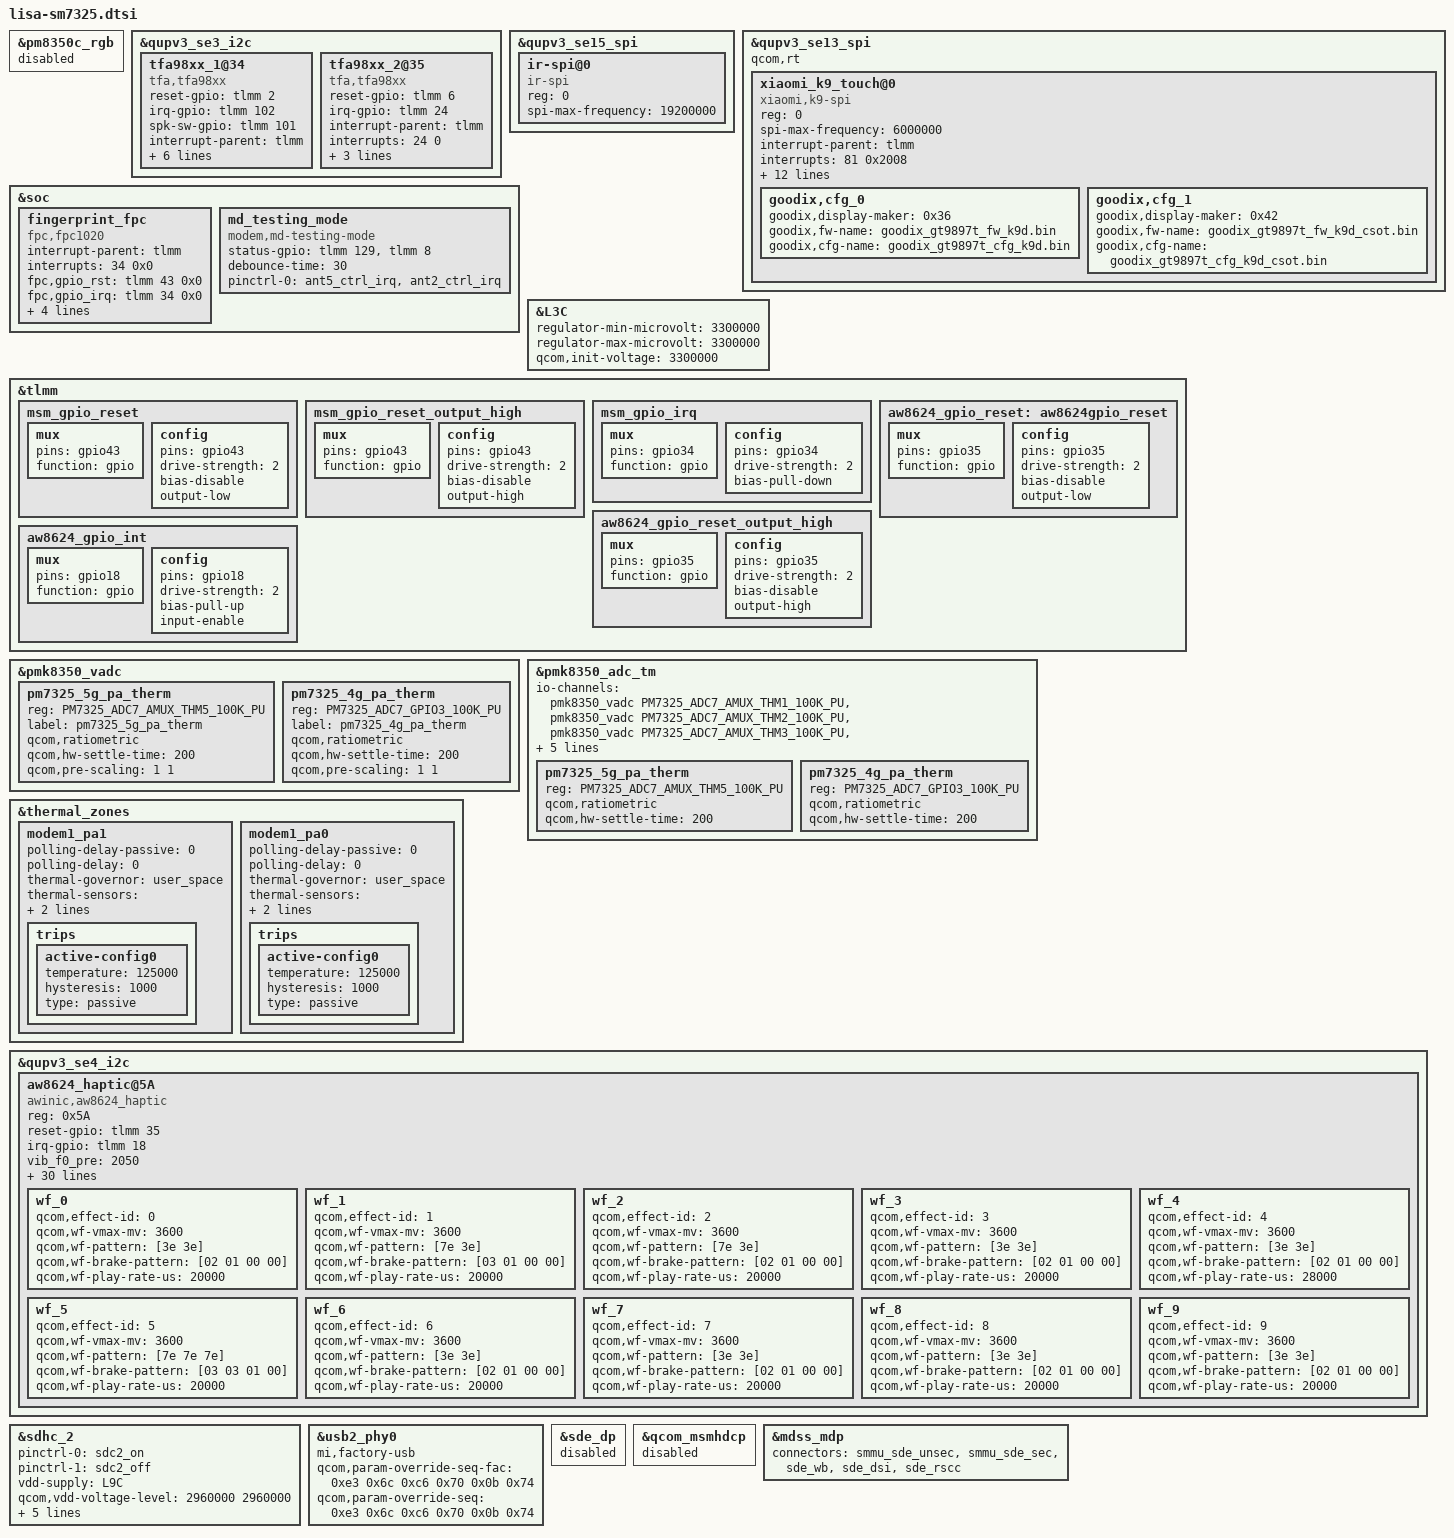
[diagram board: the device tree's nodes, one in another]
/*
this file is for attribution only of lisa
And public attribution of xiaomi platforms
*/

#include "lisa-pinctrl.dtsi"
#include "xiaomi-sm7325-common.dtsi"
#include "camera/lisa-sm7325-camera-sensor.dtsi"
#include "lisa-audio-overlay.dtsi"

&pm8350c_rgb {
	status = "disabled";
};

&qupv3_se3_i2c {
	status = "ok";
	tfa98xx_1@34 {
		compatible = "tfa,tfa98xx";
		reset-gpio = <&tlmm 2 0>;
		irq-gpio = <&tlmm 102 0>;
		spk-sw-gpio = <&tlmm 101 0>;
		interrupt-parent = <&tlmm>;
		interrupts = <102 0>;
		interrupt-names = "smartpa_irq";
		pinctrl-names = "default", "sleep";
		pinctrl-0 = <&smartpa_top_int_active &smartpa_enable_active &spk_sw_active>;
		pinctrl-1 = <&smartpa_top_int_suspend &smartpa_enable_suspend &spk_sw_inactive>;
		reg = <0x34>;
		status = "ok";
	};
	tfa98xx_2@35 {
		compatible = "tfa,tfa98xx";
		reset-gpio = <&tlmm 6 0>;
		irq-gpio = <&tlmm 24 0>;
		interrupt-parent = <&tlmm>;
		interrupts = <24 0>;
		interrupt-names = "smartpa_irq";
		pinctrl-names = "default", "sleep";
		pinctrl-0 = <&smartpa_bot_int_active>;
		pinctrl-1 = <&smartpa_bot_int_suspend>;
		reg = <0x35>;
		status = "ok";
	};
};

&qupv3_se15_spi {
	status = "ok";
	ir-spi@0 {
		compatible = "ir-spi";
		reg = <0>;
		spi-max-frequency = <19200000>;
		status = "ok";
	};
};

&qupv3_se13_spi {
	status = "ok";
	qcom,rt;
	xiaomi_k9_touch@0{
		compatible = "xiaomi,k9-spi";
		reg = <0>;
		spi-max-frequency = <6000000>;
		interrupt-parent = <&tlmm>;
		interrupts = <81 0x2008>;

		goodix,avdd-name = "avdd";
		goodix,iovdd-name = "iovdd";
		avdd-supply = <&L7C>;
		iovdd-supply = <&L2C>;

		goodix,reset-gpio = <&tlmm 105 0x00>;
		goodix,irq-gpio = <&tlmm 81 0x2800>;
		goodix,irq-flags = <2>;
		goodix,panel-max-x = <1080>;
		goodix,panel-max-y = <2400>;
		goodix,panel-max-w = <255>;
		goodix,panel-max-p = <4096>;

		goodix,config-array-size = <2>;
		goodix,cfg_0 {
			goodix,display-maker = <0x36>;
			goodix,fw-name = "goodix_gt9897t_fw_k9d.bin";
			goodix,cfg-name = "goodix_gt9897t_cfg_k9d.bin";
		};
		goodix,cfg_1 {
			goodix,display-maker = <0x42>;
			goodix,fw-name = "goodix_gt9897t_fw_k9d_csot.bin";
			goodix,cfg-name = "goodix_gt9897t_cfg_k9d_csot.bin";
		};

		/*pinctrl-names = "pmx_ts_active", "pmx_ts_suspend", "pmx_ts_release";*/
		/*pinctrl-0 = <&mi_ts_active>;*/
		/*pinctrl-1 = <&ts_int_suspend &ts_reset_suspend>;*/
		/*pinctrl-2 = <&ts_release>;*/
		/*vdd-supply = <&touch_avdd_vreg>;*/
		/*vcc_i2c-supply = <&L2C>;*/
	};
};

&soc {
	fingerprint_fpc {
		status = "ok";
		compatible = "fpc,fpc1020";
		interrupt-parent = <&tlmm>;
		interrupts = <34 0x0>;
		fpc,gpio_rst    = <&tlmm 43 0x0>;
		fpc,gpio_irq    = <&tlmm 34 0x0>;
		fp_vdd_vreg-supply = <&L3C>;
		pinctrl-names = "fpc1020_reset_reset",
						"fpc1020_reset_active",
						"fpc1020_irq_active";

		pinctrl-0 = <&msm_gpio_reset>;
		pinctrl-1 = <&msm_gpio_reset_output_high>;
		pinctrl-2 = <&msm_gpio_irq>;
	};

	md_testing_mode {
		compatible = "modem,md-testing-mode";
		status-gpio = <&tlmm 129 0x00>,
                <&tlmm 8 0x00>;
		debounce-time = <30>;
		pinctrl-names = "default";
		pinctrl-0 = <&ant5_ctrl_irq &ant2_ctrl_irq>;
	};
};

&L3C {
	regulator-min-microvolt = <3300000>;
	regulator-max-microvolt = <3300000>;
	qcom,init-voltage = <3300000>;
};

&tlmm {
                /* FP_RESET_N */
        msm_gpio_reset: msm_gpio_reset {
                mux {
                        pins = "gpio43";
                        function = "gpio";
                };
                config {
                        pins = "gpio43";
                        drive-strength = <2>;
                        bias-disable;
                        output-low;
                };
        };
                /* FP_RESET_N, state device active*/
        msm_gpio_reset_output_high: msm_gpio_reset_output_high {
                mux {
                        pins = "gpio43";
                        function = "gpio";
                };
                config {
                        pins = "gpio43";
                        drive-strength = <2>;
                        bias-disable;
                        output-high;
                };
        };
                /* FP_INT_N */
        msm_gpio_irq: msm_gpio_irq {
                mux {
                        pins = "gpio34";
                        function = "gpio";
                };
                config {
                        pins = "gpio34";
                        drive-strength = <2>;
                        bias-pull-down;
                };
        };
};

&pmk8350_vadc {
	pm7325_5g_pa_therm {
		reg = <PM7325_ADC7_AMUX_THM5_100K_PU>;
		label = "pm7325_5g_pa_therm";
		qcom,ratiometric;
		qcom,hw-settle-time = <200>;
		qcom,pre-scaling = <1 1>;
        };
	pm7325_4g_pa_therm {
		reg = <PM7325_ADC7_GPIO3_100K_PU>;
                label = "pm7325_4g_pa_therm";
		qcom,ratiometric;
		qcom,hw-settle-time = <200>;
		qcom,pre-scaling = <1 1>;
	};
};

&pmk8350_adc_tm {
	io-channels = <&pmk8350_vadc PM7325_ADC7_AMUX_THM1_100K_PU>,
			<&pmk8350_vadc PM7325_ADC7_AMUX_THM2_100K_PU>,
			<&pmk8350_vadc PM7325_ADC7_AMUX_THM3_100K_PU>,
			<&pmk8350_vadc PM7325_ADC7_AMUX_THM4_100K_PU>,
			<&pmk8350_vadc PMK8350_ADC7_AMUX_THM1_100K_PU>,
                        <&pmk8350_vadc PM7325B_ADC7_GPIO2_100K_PU>,
                        <&pmk8350_vadc PM7325_ADC7_AMUX_THM5_100K_PU>,
                        <&pmk8350_vadc PM7325_ADC7_GPIO3_100K_PU>;
	pm7325_5g_pa_therm {
		reg = <PM7325_ADC7_AMUX_THM5_100K_PU>;
		qcom,ratiometric;
		qcom,hw-settle-time = <200>;
	};
	pm7325_4g_pa_therm {
		reg = <PM7325_ADC7_GPIO3_100K_PU>;
		qcom,ratiometric;
		qcom,hw-settle-time = <200>;
	};
};

&thermal_zones {
	modem1_pa1 {
		polling-delay-passive = <0>;
		polling-delay = <0>;
		thermal-governor = "user_space";
		thermal-sensors = <&pmk8350_adc_tm PM7325_ADC7_AMUX_THM5_100K_PU>;
		wake-capable-sensor;
		trips {
			active-config0 {
				temperature = <125000>;
				hysteresis = <1000>;
				type = "passive";
			};
		};
	};

	modem1_pa0 {
		polling-delay-passive = <0>;
		polling-delay = <0>;
		thermal-governor = "user_space";
		thermal-sensors = <&pmk8350_adc_tm PM7325_ADC7_GPIO3_100K_PU>;
		wake-capable-sensor;
		trips {
			active-config0 {
				temperature = <125000>;
				hysteresis = <1000>;
				type = "passive";
			};
		};
	};
};
&qupv3_se4_i2c {
     status = "ok";
     aw8624_haptic@5A {
		compatible = "awinic,aw8624_haptic";
		reg = <0x5A>;
		reset-gpio = <&tlmm 35 0>;
		irq-gpio = <&tlmm 18 0>;
		vib_f0_pre = < 2050 >;
		vib_f0_cali_percen = < 7 >;
		vib_cont_drv_lev = < 106 >;
		vib_cont_drv_lvl_ov = < 155 >;
		vib_cont_td = < 0xF06C >;
		vib_cont_zc_thr = < 0x08F8 >;
		vib_cont_num_brk = < 3 >;
		vib_f0_coeff = < 260 >; /*Don't modify it*/
		vib_duration_time = < 15 60 0 0 0 >;
		vib_brake_ram_config = < 1 1 90 60 20 3 1 3 1 1 90 60 30 5 1 3 0 0 50 40 25 0 5 3 >;
		vib_brake_cont_config = < 1 1 90 42 20 5 2 2 0 0 0 0 0 0 0 0 0 0 0 0 0 0 0 0 >;
		vib_f0_trace_parameter = < 9 5 1 15 >;
		vib_bemf_config = < 0 8 3 0xf8 >;
		vib_sw_brake = < 0x2c >;
		vib_wavseq = < 0 1 1 2 0 0 0 0 0 0 0 0 0 0 0 0 >; /*wavseq1-seq8 0x07-0x0E*/
		vib_wavloop = < 0 6 1 15 0 0 0 0 0 0>;/*loop1-mainloog 0x0f-0x13*/
		vib_td_brake = < 42720 42720 42720 >; /*level0 level1 level2*/
		vib_tset = < 0x11 >;
		vib_func_parameter1 = < 1 >;
		vib_gain_flag = < 1 >;
		vib_r_spare = < 0x68 >;
		vib_bstdbg = < 0x30 0xeb 0xd4 0 0 0 >;
		vib_effect_id_boundary = < 10 >;
		vib_effect_max = < 170 >;
		vib_rtp_time = < 20 20 20 20 20 20 20 20 20 30
				 40 50 60 70 80 90 100 110 120 130
				 140 150 160 170 180 190 200 210 220 230
				 240 250 260 270 280 290 300 310 320 330
				 20 20 20 20 20 20 20 20 20 20
				 20 20 20 20 20 20 20 20 20 20
				 20 20 20 20 20 20 20 20 20 20
				 20 20 20 20 20 20 20 20 20 20
				 20 20 20 20 20 20 20 20 20 20
				 20 20 20 20 20 20 20 20 20 20
				 20 20 20 20 20 20 20 20 20 20
				 20 20 20 20 20 20 20 20 20 20
				 20 20 20 20 20 20 20 20 20 20
				 20 20 20 20 20 20 20 20 20 20
				 20 20 20 20 20 20 20 20 20 20
				 20 20 20 20 20 20 20 20 20 20
				 20 20 20 20 20 20 20 20 20 20
				 20 20 20 20 20 >;
		pinctrl-names = "aw8624_reset_reset","aw8624_reset_active","aw8624_interrupt_active";
		pinctrl-0 = <&aw8624_gpio_reset>;
		pinctrl-1 = <&aw8624_gpio_reset_output_high>;
		pinctrl-2 = <&aw8624_gpio_int>;
		wf_0 {
			/*CLICK*/
			qcom,effect-id = <0>;
			qcom,wf-vmax-mv = <3600>;
			qcom,wf-pattern = [3e 3e];
			qcom,wf-brake-pattern = [02 01 00 00];
			qcom,wf-play-rate-us = <20000>;
		};
		wf_1 {
			/*DOUBLE CLICK*/
			qcom,effect-id = <1>;
			qcom,wf-vmax-mv = <3600>;
			qcom,wf-pattern = [7e 3e];
			qcom,wf-brake-pattern = [03 01 00 00];
			qcom,wf-play-rate-us = <20000>;
		};
		wf_2 {
			/*TICK*/
			qcom,effect-id = <2>;
			qcom,wf-vmax-mv = <3600>;
			qcom,wf-pattern = [7e 3e];
			qcom,wf-brake-pattern = [02 01 00 00];
			qcom,wf-play-rate-us = <20000>;
		};
		wf_3 {
			/*THUD*/
			qcom,effect-id = <3>;
			qcom,wf-vmax-mv = <3600>;
			qcom,wf-pattern = [3e 3e];
			qcom,wf-brake-pattern = [02 01 00 00];
			qcom,wf-play-rate-us = <20000>;
		};
		wf_4 {
			/*POP*/
			qcom,effect-id = <4>;
			qcom,wf-vmax-mv = <3600>;
			qcom,wf-pattern = [3e 3e];
			qcom,wf-brake-pattern = [02 01 00 00];
			qcom,wf-play-rate-us = <28000>;
		};
		wf_5 {
			/*HEAVY CLICK*/
			qcom,effect-id = <5>;
			qcom,wf-vmax-mv = <3600>;
			qcom,wf-pattern = [7e 7e 7e];
			qcom,wf-brake-pattern = [03 03 01 00];
			qcom,wf-play-rate-us = <20000>;
		};
		wf_6 {
			/*id 6*/
			qcom,effect-id = <6>;
			qcom,wf-vmax-mv = <3600>;
			qcom,wf-pattern = [3e 3e];
			qcom,wf-brake-pattern = [02 01 00 00];
			qcom,wf-play-rate-us = <20000>;
		};
		wf_7 {
			/*id 7*/
			qcom,effect-id = <7>;
			qcom,wf-vmax-mv = <3600>;
			qcom,wf-pattern = [3e 3e];
			qcom,wf-brake-pattern = [02 01 00 00];
			qcom,wf-play-rate-us = <20000>;
		};
		wf_8 {
			/*id 8*/
			qcom,effect-id = <8>;
			qcom,wf-vmax-mv = <3600>;
			qcom,wf-pattern = [3e 3e];
			qcom,wf-brake-pattern = [02 01 00 00];
			qcom,wf-play-rate-us = <20000>;
		};
		wf_9 {
			/*id 9*/
			qcom,effect-id = <9>;
			qcom,wf-vmax-mv = <3600>;
			qcom,wf-pattern = [3e 3e];
			qcom,wf-brake-pattern = [02 01 00 00];
			qcom,wf-play-rate-us = <20000>;
		};
	};
	/* AWINIC AW8624 Haptic End */
};
&tlmm {
	/* AW8624_RESET_N */
	aw8624_gpio_reset: aw8624gpio_reset {
		mux {
			pins = "gpio35";
		        function = "gpio";
		};

		config {
			pins = "gpio35";
			drive-strength = <2>;
			bias-disable;
			output-low;
		};
	};
	/* AW8624_RESET_N, state device active*/
	aw8624_gpio_reset_output_high: aw8624_gpio_reset_output_high {
		mux {
			pins = "gpio35";
			function = "gpio";
		};

		config {
			pins = "gpio35";
			drive-strength = <2>;
			bias-disable;
			output-high;
		};
	};
	/* AW8624_INTERRUPT_N */
	aw8624_gpio_int: aw8624_gpio_int {
		mux {
			pins = "gpio18";
			function = "gpio";
		};

		config {
			pins = "gpio18";
			drive-strength = <2>;
			bias-pull-up;
			input-enable;
		};
	};
};

&sdhc_2 {
	pinctrl-names = "default", "sleep";
	pinctrl-0 = <&sdc2_on>;
	pinctrl-1 = <&sdc2_off>;

	vdd-supply = <&L9C>;
	qcom,vdd-voltage-level = <2960000 2960000>;
	qcom,vdd-current-level = <0 800000>;

	vdd-io-supply = <&L6C>;
	qcom,vdd-io-voltage-level = <1800000 2960000>;
	qcom,vdd-io-current-level = <0 22000>;

	cd-gpios = <&tlmm 91 GPIO_ACTIVE_HIGH>;

	status = "ok";
};

&usb2_phy0 {
	mi,factory-usb;
	qcom,param-override-seq-fac =
		<0xe3 0x6c	/* override_x0 */
		0xc6 0x70	/* override_x1 */
		0x0b 0x74>;	/* override x2 */
	qcom,param-override-seq =
		<0xe3 0x6c	/* override_x0 */
		0xc6 0x70	/* override_x1 */
		0x0b 0x74>;	/* override x2 */
};

&sde_dp {
	status = "disabled";
};

&qcom_msmhdcp {
	status = "disabled";
};

&mdss_mdp {
	connectors = <&smmu_sde_unsec &smmu_sde_sec &sde_wb &sde_dsi
		&sde_rscc>;
};
